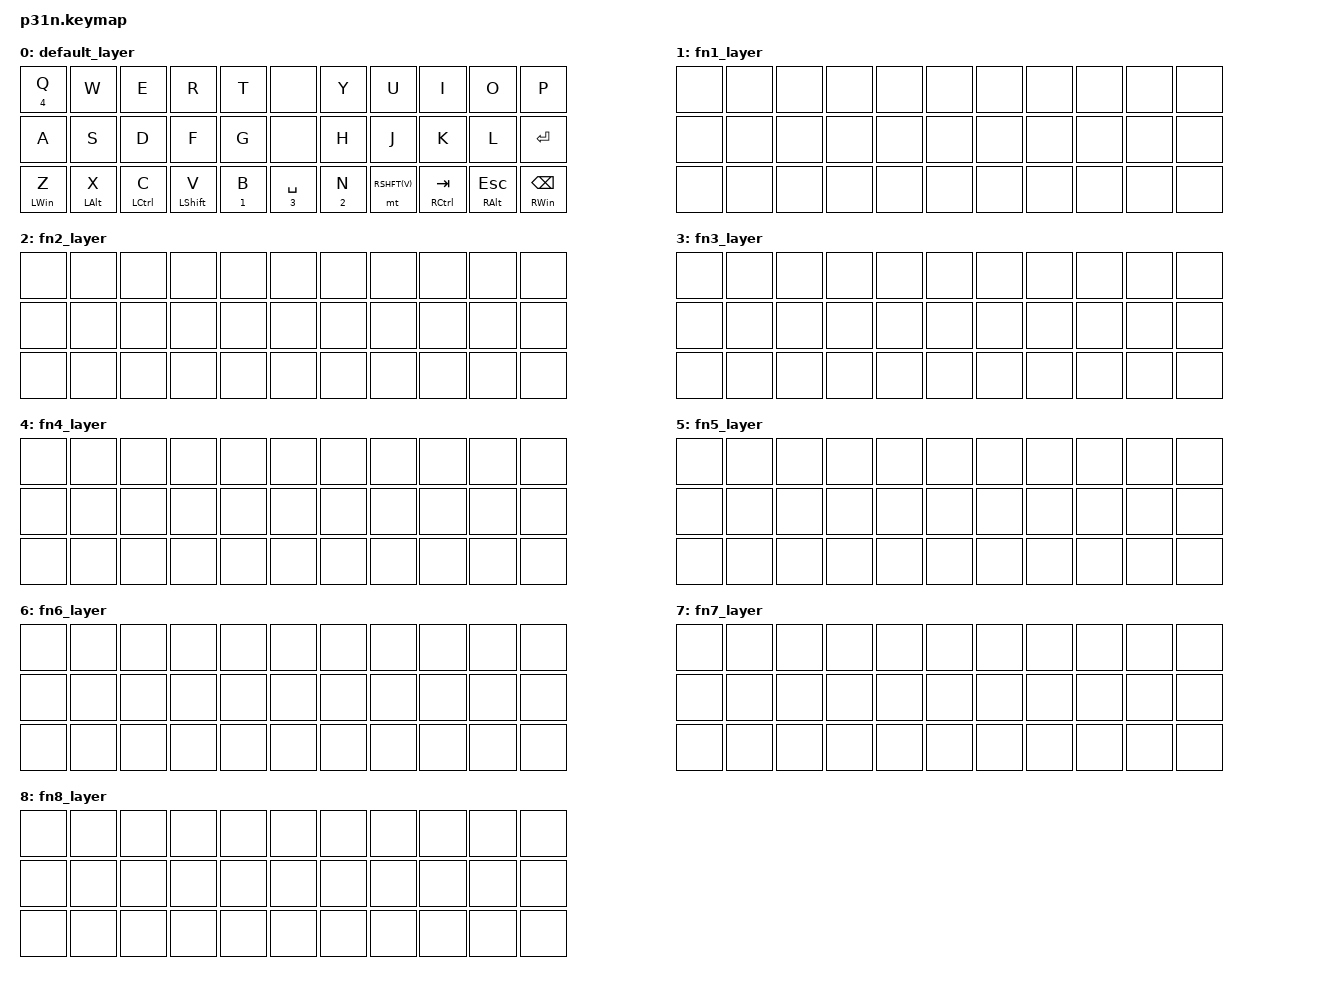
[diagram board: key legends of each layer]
/*
 * Copyright (c) 2020 The ZMK Contributors
 *
 * SPDX-License-Identifier: MIT
 */

#include <behaviors.dtsi>
#include <dt-bindings/zmk/keys.h>
#include <dt-bindings/zmk/rgb.h>
#include <dt-bindings/zmk/bt.h>
#include <dt-bindings/zmk/outputs.h>
#include <dt-bindings/zmk/ext_power.h>
#include <dt-bindings/zmk/mouse.h>

/ {
      behaviors {
        xlt: behavior_mo_tap {
            compatible = "zmk,behavior-hold-tap";
            label = "XLT";
            #binding-cells = <2>;
            flavor = "hold-preferred";
            tapping-term-ms = <200>;
            bindings = <&xmo>, <&kp>;
        };

        xbootloader: tap_dance_0 {
            compatible = "zmk,behavior-tap-dance";
            label = "XBOOTLOADER";
            #binding-cells = <0>;
            tapping-term-ms = <500>;
            bindings = <&kp C_PP>, <&bootloader>;
        };
      };

      macros {
        cut2home: cut2home {
            compatible = "zmk,behavior-macro";
            label = "CUT2HOME";
            #binding-cells = <0>;            
            bindings = <&kp LS(HOME) &kp LC(C) &kp BSPC>;
            wait-ms = <1>;
            tap-ms = <1>;
        };

        cut2end: cut2end {
            compatible = "zmk,behavior-macro";
            label = "CUT2END";
            #binding-cells = <0>;
            bindings = <&kp LS(END) &kp LC(C) &kp DEL>;
            wait-ms = <1>;
            tap-ms = <1>;
        };

        cutline: cutline {
            compatible = "zmk,behavior-macro";
            label = "CUTLINE";
            #binding-cells = <0>;
            bindings = <&kp HOME &kp LS(END) &kp LS(RIGHT) &kp LC(C) &kp DEL>;
            wait-ms = <1>;
            tap-ms = <1>;
        };

        xtips: xtips {
            compatible = "zmk,behavior-macro";
            label = "XTIPS";
            #binding-cells = <0>;
            bindings = <&kp LS(X) &kp KP_DOT &kp LS(T) &kp I &kp P &kp S>;
            wait-ms = <1>;
            tap-ms = <1>;
        };

        xmo: xmo {
            compatible = "zmk,behavior-macro-one-param";
            label = "XMO";
            #binding-cells = <1>;
            bindings
            = <&macro_param_1to1>
            , <&macro_press &mo MACRO_PLACEHOLDER>
            , <&macro_tap &rgb_ug RGB_EFF>
            , <&macro_tap &rgb_ug RGB_COLOR_HSB(0,0,90)>
            , <&macro_pause_for_release>
            , <&macro_param_1to1>
            , <&macro_release &mo MACRO_PLACEHOLDER>
            , <&macro_tap &rgb_ug RGB_EFR>
            , <&macro_tap &rgb_ug RGB_COLOR_HSB(250,90,90)>;
            wait-ms = <0>;
            tap-ms = <0>;
        };
      };

	keymap0: keymap {
		compatible = "zmk,keymap";

		default_layer {
            // |   Q   |   W   |   E   |   R   |   T   |    ----   |   Y   |   U   |   I    |   O    |   P   |
            // |   A   |   S   |   D   |   F   |   G   |    ----   |   H   |   J   |   K    |   L    |  Ent  |
            // | LG,Z  |  LA,X | LC,C  | LS,V  | LT1,B | LT3,SPACE | LT2,N | RS,M  | RS,TAb | RA,ESC | RG,BS | 
            bindings = <
            &xlt 4 Q     &kp W        &kp E         &kp R        &kp T      &none         &kp Y      &kp U         &kp I          &kp O          &kp P    
            &kp A        &kp S        &kp D         &kp F        &kp G      &none         &kp H      &kp J         &kp K          &kp L          &kp ENTER
            &mt LWIN Z   &mt LALT X   &mt LCTRL C   &mt LSHFT V  &xlt 1 B   &xlt 3 SPACE  &xlt 2 N   &mt RSHFT(V)  &mt RCTRL TAB  &mt RALT ESC   &mt RWIN BSPC
            >;
		};

		fn1_layer {
            bindings = <
            &none   &none   &none   &none    &none   &none   &none   &none   &none   &none   &none  
            &none   &none   &none   &none    &none   &none   &none   &none   &none   &none   &none  
            &none   &none   &none   &none    &none   &none   &none   &none   &none   &none   &none      
             >;
		};

		fn2_layer {
            bindings = <
            &none   &none   &none   &none    &none   &none   &none   &none   &none   &none   &none  
            &none   &none   &none   &none    &none   &none   &none   &none   &none   &none   &none  
            &none   &none   &none   &none    &none   &none   &none   &none   &none   &none   &none      
            >;
		};

		fn3_layer {
            bindings = <
            &none   &none   &none   &none    &none   &none   &none   &none   &none   &none   &none  
            &none   &none   &none   &none    &none   &none   &none   &none   &none   &none   &none  
            &none   &none   &none   &none    &none   &none   &none   &none   &none   &none   &none      
            >;
		};
		
		fn4_layer {
            bindings = <
            &none   &none   &none   &none    &none   &none   &none   &none   &none   &none   &none  
            &none   &none   &none   &none    &none   &none   &none   &none   &none   &none   &none  
            &none   &none   &none   &none    &none   &none   &none   &none   &none   &none   &none      
            >;
		};

		fn5_layer {
            bindings = <
            &none   &none   &none   &none    &none   &none   &none   &none   &none   &none   &none  
            &none   &none   &none   &none    &none   &none   &none   &none   &none   &none   &none  
            &none   &none   &none   &none    &none   &none   &none   &none   &none   &none   &none      
            >;
		};
		
		fn6_layer {
            bindings = <
            &none   &none   &none   &none    &none   &none   &none   &none   &none   &none   &none  
            &none   &none   &none   &none    &none   &none   &none   &none   &none   &none   &none  
            &none   &none   &none   &none    &none   &none   &none   &none   &none   &none   &none      
            >;
		};
		
		fn7_layer {
            bindings = <
            &none   &none   &none   &none    &none   &none   &none   &none   &none   &none   &none  
            &none   &none   &none   &none    &none   &none   &none   &none   &none   &none   &none  
            &none   &none   &none   &none    &none   &none   &none   &none   &none   &none   &none      
            >;
		};
		
		fn8_layer {
            bindings = <
            &none   &none   &none   &none    &none   &none   &none   &none   &none   &none   &none  
            &none   &none   &none   &none    &none   &none   &none   &none   &none   &none   &none  
            &none   &none   &none   &none    &none   &none   &none   &none   &none   &none   &none      
            >;
		};
	};
};
